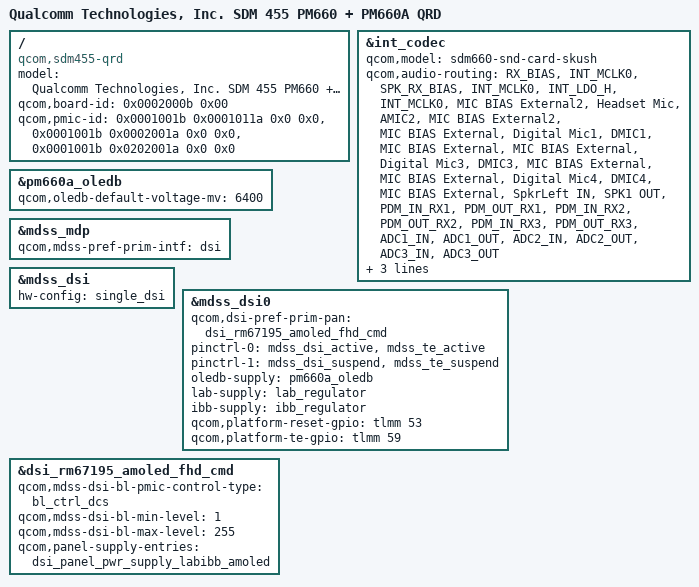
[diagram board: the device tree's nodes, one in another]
/* Copyright (c) 2018, The Linux Foundation. All rights reserved.
 *
 * This program is free software; you can redistribute it and/or modify
 * it under the terms of the GNU General Public License version 2 and
 * only version 2 as published by the Free Software Foundation.
 *
 * This program is distributed in the hope that it will be useful,
 * but WITHOUT ANY WARRANTY; without even the implied warranty of
 * MERCHANTABILITY or FITNESS FOR A PARTICULAR PURPOSE.  See the
 * GNU General Public License for more details.
 */


/dts-v1/;

#include "sdm455.dtsi"
#include "sdm455-qrd.dtsi"
#include "msm-pm660a.dtsi"
#include "sdm660-internal-codec.dtsi"

/ {
	model = "Qualcomm Technologies, Inc. SDM 455 PM660 + PM660A QRD";
	compatible = "qcom,sdm455-qrd", "qcom,sdm455", "qcom,qrd";
	qcom,board-id = <0x0002000b 0x00>;
	qcom,pmic-id = <0x0001001b 0x0001011a 0x0 0x0>,
			<0x0001001b 0x0002001a 0x0 0x0>,
			<0x0001001b 0x0202001a 0x0 0x0>;
};

&int_codec {
	qcom,model = "sdm660-snd-card-skush";
	/delete-property/ qcom,us-euro-gpios;
	qcom,audio-routing =
		"RX_BIAS", "INT_MCLK0",
		"SPK_RX_BIAS", "INT_MCLK0",
		"INT_LDO_H", "INT_MCLK0",
		"MIC BIAS External2", "Headset Mic",
		"AMIC2", "MIC BIAS External2",
		"MIC BIAS External", "Digital Mic1",
		"DMIC1", "MIC BIAS External",
		"MIC BIAS External", "Digital Mic3",
		"DMIC3", "MIC BIAS External",
		"MIC BIAS External", "Digital Mic4",
		"DMIC4", "MIC BIAS External",
		"SpkrLeft IN", "SPK1 OUT",
		"PDM_IN_RX1", "PDM_OUT_RX1",
		"PDM_IN_RX2", "PDM_OUT_RX2",
		"PDM_IN_RX3", "PDM_OUT_RX3",
		"ADC1_IN", "ADC1_OUT",
		"ADC2_IN", "ADC2_OUT",
		"ADC3_IN", "ADC3_OUT";
	qcom,wsa-max-devs = <1>;
	qcom,wsa-devs = <&wsa881x_211_en>, <&wsa881x_213_en>;
	qcom,wsa-aux-dev-prefix = "SpkrLeft", "SpkrLeft";
};

&pm660a_oledb {
	status = "okay";
	qcom,oledb-default-voltage-mv = <6400>;
};

&mdss_mdp {
	qcom,mdss-pref-prim-intf = "dsi";
};

&mdss_dsi {
	hw-config = "single_dsi";
};

&mdss_dsi0 {
	qcom,dsi-pref-prim-pan = <&dsi_rm67195_amoled_fhd_cmd>;
	pinctrl-names = "mdss_default", "mdss_sleep";
	pinctrl-0 = <&mdss_dsi_active &mdss_te_active>;
	pinctrl-1 = <&mdss_dsi_suspend &mdss_te_suspend>;
	oledb-supply = <&pm660a_oledb>;
	lab-supply = <&lab_regulator>;
	ibb-supply = <&ibb_regulator>;
	qcom,platform-reset-gpio = <&tlmm 53 0>;
	qcom,platform-te-gpio = <&tlmm 59 0>;
};

&dsi_rm67195_amoled_fhd_cmd {
	qcom,mdss-dsi-bl-pmic-control-type = "bl_ctrl_dcs";
	qcom,mdss-dsi-bl-min-level = <1>;
	qcom,mdss-dsi-bl-max-level = <255>;
	qcom,panel-supply-entries = <&dsi_panel_pwr_supply_labibb_amoled>;
};
